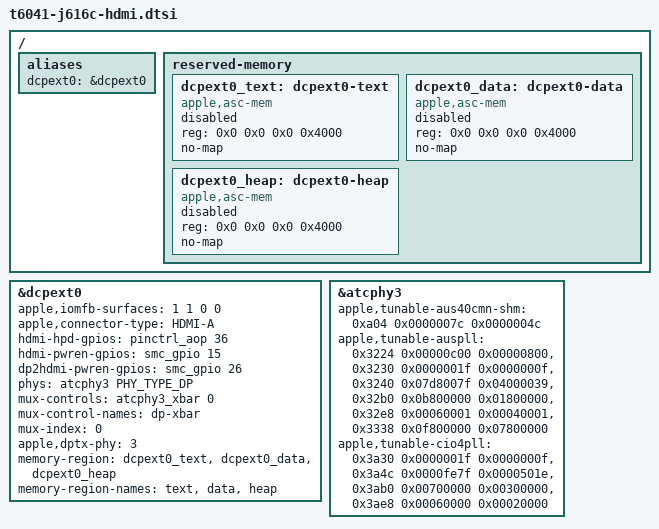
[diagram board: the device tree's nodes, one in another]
// SPDX-License-Identifier: GPL-2.0+ OR MIT
/*
 * HDMI output of the J616c: dcpext0, the ATC3 display crossbar, atcphy3 (a
 * DP PHY without a USB controller) and the on-board DP-to-HDMI converter.
 *
 * Every node is disabled. No DISPEXT0 power domain is described: the chain
 * runs as iBoot leaves it powered. The boot loader fills dcpext0's firmware
 * memory (the regions below; it points the text region at the internal
 * DCP's), and the display gate (drivers/soc/apple/display-gate.c) then
 * enables the chain and adds dispext0's DART to the display subsystem's
 * iommus.
 */

/ {
	aliases {
		dcpext0 = &dcpext0;
	};

	reserved-memory {
		/*
		 * The loader replaces this placeholder with the internal DCP's
		 * TEXT, which the external processors share, as on the M4 Pro.
		 */
		dcpext0_text: dcpext0-text {
			compatible = "apple,asc-mem";
			reg = <0x0 0x0 0x0 0x4000>;
			no-map;
			status = "disabled";
		};

		dcpext0_data: dcpext0-data {
			compatible = "apple,asc-mem";
			reg = <0x0 0x0 0x0 0x4000>;
			no-map;
			status = "disabled";
		};

		dcpext0_heap: dcpext0-heap {
			compatible = "apple,asc-mem";
			reg = <0x0 0x0 0x0 0x4000>;
			no-map;
			status = "disabled";
		};
	};
};

&dcpext0 {
	/delete-property/ apple,typec-hybrid-first;
	apple,iomfb-surfaces = <1 1 0 0>;
	apple,connector-type = "HDMI-A";
	hdmi-hpd-gpios = <&pinctrl_aop 36 GPIO_ACTIVE_HIGH>;
	hdmi-pwren-gpios = <&smc_gpio 15 GPIO_ACTIVE_HIGH>;
	dp2hdmi-pwren-gpios = <&smc_gpio 26 GPIO_ACTIVE_HIGH>;
	phys = <&atcphy3 PHY_TYPE_DP>;
	phy-names = "dp-phy";
	mux-controls = <&atcphy3_xbar 0>;
	mux-control-names = "dp-xbar";
	mux-index = <0>;
	apple,dptx-phy = <3>;
	memory-region = <&dcpext0_text>, <&dcpext0_data>, <&dcpext0_heap>;
	memory-region-names = "text", "data", "heap";
};

&atcphy3 {
	apple,tunable-aus40cmn-shm =
		<0xa04 0x0000007c 0x0000004c>;
	apple,tunable-auspll =
		<0x3224 0x00000c00 0x00000800>,
		<0x3230 0x0000001f 0x0000000f>,
		<0x3240 0x07d8007f 0x04000039>,
		<0x32b0 0x0b800000 0x01800000>,
		<0x32e8 0x00060001 0x00040001>,
		<0x3338 0x0f800000 0x07800000>;
	apple,tunable-cio4pll =
		<0x3a30 0x0000001f 0x0000000f>,
		<0x3a4c 0x0000fe7f 0x0000501e>,
		<0x3ab0 0x00700000 0x00300000>,
		<0x3ae8 0x00060000 0x00020000>;
};
